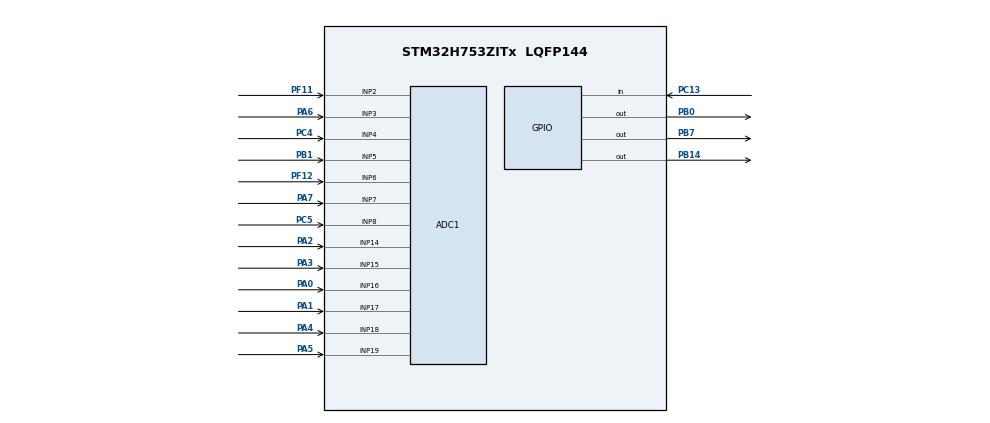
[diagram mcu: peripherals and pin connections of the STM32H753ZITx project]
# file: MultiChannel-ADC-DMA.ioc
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ADC1.Channel-0\#ChannelRegularConversion=ADC_CHANNEL_2
ADC1.Channel-1\#ChannelRegularConversion=ADC_CHANNEL_3
ADC1.Channel-10\#ChannelRegularConversion=ADC_CHANNEL_17
ADC1.Channel-11\#ChannelRegularConversion=ADC_CHANNEL_18
ADC1.Channel-12\#ChannelRegularConversion=ADC_CHANNEL_19
ADC1.Channel-2\#ChannelRegularConversion=ADC_CHANNEL_4
ADC1.Channel-3\#ChannelRegularConversion=ADC_CHANNEL_5
ADC1.Channel-4\#ChannelRegularConversion=ADC_CHANNEL_6
ADC1.Channel-5\#ChannelRegularConversion=ADC_CHANNEL_7
ADC1.Channel-6\#ChannelRegularConversion=ADC_CHANNEL_8
ADC1.Channel-7\#ChannelRegularConversion=ADC_CHANNEL_14
ADC1.Channel-8\#ChannelRegularConversion=ADC_CHANNEL_15
ADC1.Channel-9\#ChannelRegularConversion=ADC_CHANNEL_16
ADC1.ClockPrescaler=ADC_CLOCK_ASYNC_DIV8
ADC1.ContinuousConvMode=DISABLE
ADC1.ConversionDataManagement=ADC_CONVERSIONDATA_DMA_CIRCULAR
ADC1.EOCSelection=ADC_EOC_SEQ_CONV
ADC1.ExternalTrigConv=ADC_EXTERNALTRIG_T8_TRGO
ADC1.NbrOfConversion=13
ADC1.NbrOfConversionFlag=1
ADC1.OffsetNumber-0\#ChannelRegularConversion=ADC_OFFSET_NONE
ADC1.OffsetNumber-1\#ChannelRegularConversion=ADC_OFFSET_NONE
ADC1.OffsetNumber-10\#ChannelRegularConversion=ADC_OFFSET_NONE
ADC1.OffsetNumber-11\#ChannelRegularConversion=ADC_OFFSET_NONE
ADC1.OffsetNumber-12\#ChannelRegularConversion=ADC_OFFSET_NONE
ADC1.OffsetNumber-2\#ChannelRegularConversion=ADC_OFFSET_NONE
ADC1.OffsetNumber-3\#ChannelRegularConversion=ADC_OFFSET_NONE
ADC1.OffsetNumber-4\#ChannelRegularConversion=ADC_OFFSET_NONE
ADC1.OffsetNumber-5\#ChannelRegularConversion=ADC_OFFSET_NONE
ADC1.OffsetNumber-6\#ChannelRegularConversion=ADC_OFFSET_NONE
ADC1.OffsetNumber-7\#ChannelRegularConversion=ADC_OFFSET_NONE
ADC1.OffsetNumber-8\#ChannelRegularConversion=ADC_OFFSET_NONE
ADC1.OffsetNumber-9\#ChannelRegularConversion=ADC_OFFSET_NONE
ADC1.OffsetSignedSaturation-0\#ChannelRegularConversion=DISABLE
ADC1.OffsetSignedSaturation-1\#ChannelRegularConversion=DISABLE
ADC1.OffsetSignedSaturation-10\#ChannelRegularConversion=DISABLE
ADC1.OffsetSignedSaturation-11\#ChannelRegularConversion=DISABLE
ADC1.OffsetSignedSaturation-12\#ChannelRegularConversion=DISABLE
ADC1.OffsetSignedSaturation-2\#ChannelRegularConversion=DISABLE
ADC1.OffsetSignedSaturation-3\#ChannelRegularConversion=DISABLE
ADC1.OffsetSignedSaturation-4\#ChannelRegularConversion=DISABLE
ADC1.OffsetSignedSaturation-5\#ChannelRegularConversion=DISABLE
ADC1.OffsetSignedSaturation-6\#ChannelRegularConversion=DISABLE
ADC1.OffsetSignedSaturation-7\#ChannelRegularConversion=DISABLE
ADC1.OffsetSignedSaturation-8\#ChannelRegularConversion=DISABLE
ADC1.OffsetSignedSaturation-9\#ChannelRegularConversion=DISABLE
ADC1.Rank-0\#ChannelRegularConversion=1
ADC1.Rank-1\#ChannelRegularConversion=2
ADC1.Rank-10\#ChannelRegularConversion=11
ADC1.Rank-11\#ChannelRegularConversion=12
ADC1.Rank-12\#ChannelRegularConversion=13
ADC1.Rank-2\#ChannelRegularConversion=3
ADC1.Rank-3\#ChannelRegularConversion=4
ADC1.Rank-4\#ChannelRegularConversion=5
ADC1.Rank-5\#ChannelRegularConversion=6
ADC1.Rank-6\#ChannelRegularConversion=7
ADC1.Rank-7\#ChannelRegularConversion=8
ADC1.Rank-8\#ChannelRegularConversion=9
ADC1.Rank-9\#ChannelRegularConversion=10
ADC1.SamplingTime-0\#ChannelRegularConversion=ADC_SAMPLETIME_387CYCLES_5
ADC1.SamplingTime-1\#ChannelRegularConversion=ADC_SAMPLETIME_387CYCLES_5
ADC1.SamplingTime-10\#ChannelRegularConversion=ADC_SAMPLETIME_810CYCLES_5
ADC1.SamplingTime-11\#ChannelRegularConversion=ADC_SAMPLETIME_810CYCLES_5
ADC1.SamplingTime-12\#ChannelRegularConversion=ADC_SAMPLETIME_810CYCLES_5
ADC1.SamplingTime-2\#ChannelRegularConversion=ADC_SAMPLETIME_387CYCLES_5
ADC1.SamplingTime-3\#ChannelRegularConversion=ADC_SAMPLETIME_387CYCLES_5
ADC1.SamplingTime-4\#ChannelRegularConversion=ADC_SAMPLETIME_387CYCLES_5
ADC1.SamplingTime-5\#ChannelRegularConversion=ADC_SAMPLETIME_810CYCLES_5
ADC1.SamplingTime-6\#ChannelRegularConversion=ADC_SAMPLETIME_810CYCLES_5
ADC1.SamplingTime-7\#ChannelRegularConversion=ADC_SAMPLETIME_810CYCLES_5
ADC1.SamplingTime-8\#ChannelRegularConversion=ADC_SAMPLETIME_810CYCLES_5
ADC1.SamplingTime-9\#ChannelRegularConversion=ADC_SAMPLETIME_810CYCLES_5
ADC1.master=1
CORTEX_M7.AccessPermission_Spec=MPU_REGION_FULL_ACCESS
CORTEX_M7.BaseAddress_Spec=0x38000000
CORTEX_M7.CPU_DCache=Enabled
CORTEX_M7.CPU_ICache=Enabled
CORTEX_M7.IsShareable_Spec=MPU_ACCESS_NOT_SHAREABLE
CORTEX_M7.MPU_Control=MPU_PRIVILEGED_DEFAULT
CORTEX_M7.Size_Spec=MPU_REGION_SIZE_32KB
CORTEX_M7.SubRegionDisable_Spec=0x00
CORTEX_M7.default_mode_Activation=1
Dma.ADC1.0.Direction=DMA_PERIPH_TO_MEMORY
Dma.ADC1.0.EventEnable=DISABLE
Dma.ADC1.0.FIFOMode=DMA_FIFOMODE_DISABLE
Dma.ADC1.0.Instance=DMA1_Stream0
Dma.ADC1.0.MemDataAlignment=DMA_MDATAALIGN_HALFWORD
Dma.ADC1.0.MemInc=DMA_MINC_ENABLE
Dma.ADC1.0.Mode=DMA_CIRCULAR
Dma.ADC1.0.PeriphDataAlignment=DMA_PDATAALIGN_HALFWORD
Dma.ADC1.0.PeriphInc=DMA_PINC_DISABLE
Dma.ADC1.0.Polarity=HAL_DMAMUX_REQ_GEN_RISING
Dma.ADC1.0.Priority=DMA_PRIORITY_LOW
Dma.ADC1.0.RequestNumber=1
Dma.ADC1.0.SignalID=NONE
Dma.ADC1.0.SyncEnable=DISABLE
Dma.ADC1.0.SyncPolarity=HAL_DMAMUX_SYNC_NO_EVENT
Dma.ADC1.0.SyncRequestNumber=1
Dma.ADC1.0.SyncSignalID=NONE
Dma.Request0=ADC1
Mcu.Family=STM32H7
Mcu.Name=STM32H753ZITx
Mcu.Package=LQFP144
NUCLEO-H753ZI.BUTTON=1
NUCLEO-H753ZI.LD1=true
NUCLEO-H753ZI.LD2=true
NUCLEO-H753ZI.LD3=true
NUCLEO-H753ZI.VCP=true
NVIC.ADC_IRQn=true\:0\:0\:false\:false\:true\:true\:true\:true
NVIC.DMA1_Stream0_IRQn=true\:0\:0\:false\:false\:true\:false\:true\:true
NVIC.EXTI15_10_IRQn=true\:0\:0\:false\:false\:true\:false\:true\:true
NVIC.PriorityGroup=NVIC_PRIORITYGROUP_4
PA0.Mode=IN16-Single-Ended
PA0.Signal=ADC1_INP16
PA1.Mode=IN17-Single-Ended
PA1.Signal=ADC1_INP17
PA2.Signal=ADCx_INP14
PA3.Signal=ADCx_INP15
PA4.Signal=ADCx_INP18
PA5.Signal=ADCx_INP19
PA6.Signal=ADCx_INP3
PA7.Signal=ADCx_INP7
PB0.Signal=GPIO_Output
PB1.Signal=ADCx_INP5
PB14.Signal=GPIO_Output
PB7.Signal=GPIO_Output
PC13.Signal=GPIO_Input
PC14-OSC32_IN\ (OSC32_IN).Mode=LSE-External-Oscillator
PC14-OSC32_IN\ (OSC32_IN).Signal=RCC_OSC32_IN
PC15-OSC32_OUT\ (OSC32_OUT).Mode=LSE-External-Oscillator
PC15-OSC32_OUT\ (OSC32_OUT).Signal=RCC_OSC32_OUT
PC4.Signal=ADCx_INP4
PC5.Signal=ADCx_INP8
PD8.Signal=USART3_TX
PD9.Signal=USART3_RX
PF11.Mode=IN2-Single-Ended
PF11.Signal=ADC1_INP2
PF12.Mode=IN6-Single-Ended
PF12.Signal=ADC1_INP6
PH0-OSC_IN\ (PH0).Signal=RCC_OSC_IN
PH1-OSC_OUT\ (PH1).Signal=RCC_OSC_OUT
ProjectManager.HeapSize=0x200
ProjectManager.StackSize=0x400
ProjectManager.TargetToolchain=STM32CubeIDE
RCC.ADCFreq_Value=32000000
RCC.APB1Freq_Value=120000000
RCC.APB2Freq_Value=120000000
RCC.APB3Freq_Value=120000000
RCC.APB4Freq_Value=120000000
RCC.CortexFreq_Value=480000000
RCC.D1PPRE=RCC_APB3_DIV2
RCC.D2PPRE1=RCC_APB1_DIV2
RCC.D2PPRE2=RCC_APB2_DIV2
RCC.D3PPRE=RCC_APB4_DIV2
RCC.DIVM1=4
RCC.DIVM2=4
RCC.DIVN1=60
RCC.DIVN2=16
RCC.DIVN3=64
RCC.DIVP2=8
RCC.DIVQ1=4
RCC.HCLKFreq_Value=240000000
RCC.HPRE=RCC_HCLK_DIV2
RCC.HSE_VALUE=8000000
RCC.PLL2FRACN=0
RCC.PLL3FRACN=0
RCC.PLLFRACN=0
RCC.PWR_Regulator_Voltage_Scale=PWR_REGULATOR_VOLTAGE_SCALE0
RCC.SYSCLKFreq_VALUE=480000000
RCC.SYSCLKSource=RCC_SYSCLKSOURCE_PLLCLK
RCC.USBFreq_Value=240000000
SH.ADCx_INP14.0=ADC1_INP14,IN14-Single-Ended
SH.ADCx_INP15.0=ADC1_INP15,IN15-Single-Ended
SH.ADCx_INP18.0=ADC1_INP18,IN18-Single-Ended
SH.ADCx_INP19.0=ADC1_INP19,IN19-Single-Ended
SH.ADCx_INP3.0=ADC1_INP3,IN3-Single-Ended
SH.ADCx_INP4.0=ADC1_INP4,IN4-Single-Ended
SH.ADCx_INP5.0=ADC1_INP5,IN5-Single-Ended
SH.ADCx_INP7.0=ADC1_INP7,IN7-Single-Ended
SH.ADCx_INP8.0=ADC1_INP8,IN8-Single-Ended
TIM8.Period=200-1
TIM8.Prescaler=24000-1
TIM8.TIM_MasterOutputTrigger=TIM_TRGO_UPDATE
VP_MEMORYMAP_VS_MEMORYMAP.Mode=CurAppReg
VP_NUCLEO-H753ZI_VS_BSP_COMMON.Mode=COMMON
VP_TIM8_VS_ClockSourceINT.Mode=Internal
board=NUCLEO-H753ZI

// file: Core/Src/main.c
/* USER CODE BEGIN Header */
/**
  ******************************************************************************
  * @file           : main.c
  * @brief          : Main program body
  ******************************************************************************
  * @attention
  *
  * Copyright (c) 2025 STMicroelectronics.
  * All rights reserved.
  *
  * This software is licensed under terms that can be found in the LICENSE file
  * in the root directory of this software component.
  * If no LICENSE file comes with this software, it is provided AS-IS.
  *
  ******************************************************************************
  */
/* USER CODE END Header */
#include "main.h"

/* USER CODE BEGIN PD */
#define NUM_OF_CONVERSIONS 13
#define ADC_RAW_VOLTAGE 0.00005035477f
/* USER CODE END PD */

COM_InitTypeDef BspCOMInit;
ADC_HandleTypeDef hadc1;
DMA_HandleTypeDef hdma_adc1;

TIM_HandleTypeDef htim8;

/* USER CODE BEGIN PV */
volatile uint16_t adcData[NUM_OF_CONVERSIONS] __attribute__((section(".nocache")));
volatile float    sensorVoltage[NUM_OF_CONVERSIONS];
/* USER CODE END PV */

void SystemClock_Config(void);
static void MPU_Config(void);
static void MX_GPIO_Init(void);
static void MX_DMA_Init(void);
static void MX_ADC1_Init(void);
static void MX_TIM8_Init(void);

/* USER CODE BEGIN 0 */
void HAL_ADC_ConvCpltCallback(ADC_HandleTypeDef *had) {
	for (uint8_t index = 0; index<NUM_OF_CONVERSIONS; index++) {
		sensorVoltage[index] = ADC_RAW_VOLTAGE * (float) adcData[index];
	}
}
/* USER CODE END 0 */

int main(void)
{

  /* MPU Configuration--------------------------------------------------------*/
  MPU_Config();

  /* Enable the CPU Cache */

  /* Enable I-Cache---------------------------------------------------------*/
  SCB_EnableICache();

  /* Enable D-Cache---------------------------------------------------------*/
  SCB_EnableDCache();

  /* MCU Configuration--------------------------------------------------------*/

  /* Reset of all peripherals, Initializes the Flash interface and the Systick. */
  HAL_Init();

  /* Configure the system clock */
  SystemClock_Config();

  /* Initialize all configured peripherals */
  MX_GPIO_Init();
  MX_DMA_Init();
  MX_ADC1_Init();
  MX_TIM8_Init();
  /* USER CODE BEGIN 2 */
  HAL_ADCEx_Calibration_Start(&hadc1, ADC_CALIB_OFFSET, ADC_SINGLE_ENDED);//Calibrating ADC before enbaling conversions
  HAL_ADC_Start_DMA(&hadc1, (uint32_t *)adcData, NUM_OF_CONVERSIONS);//Starting DMA based ADC
  HAL_TIM_Base_Start(&htim8); //50Hz sampling frequency
  /* USER CODE END 2 */

  /* Initialize leds */
  BSP_LED_Init(LED_GREEN);
  BSP_LED_Init(LED_BLUE);
  BSP_LED_Init(LED_RED);

  /* Initialize USER push-button, will be used to trigger an interrupt each time it's pressed.*/
  BSP_PB_Init(BUTTON_USER, BUTTON_MODE_EXTI);

  /* Initialize COM1 port (115200, 8 bits (7-bit data + 1 stop bit), no parity */
  BspCOMInit.BaudRate   = 115200;
  BspCOMInit.WordLength = COM_WORDLENGTH_8B;
  BspCOMInit.StopBits   = COM_STOPBITS_1;
  BspCOMInit.Parity     = COM_PARITY_NONE;
  BspCOMInit.HwFlowCtl  = COM_HWCONTROL_NONE;
  if (BSP_COM_Init(COM1, &BspCOMInit) != BSP_ERROR_NONE)
  {
    Error_Handler();
  }

  /* Infinite loop */
  while (1)
  {

  }
}

void SystemClock_Config(void)
{
  RCC_OscInitTypeDef RCC_OscInitStruct = {0};
  RCC_ClkInitTypeDef RCC_ClkInitStruct = {0};

  /** Supply configuration update enable
  */
  HAL_PWREx_ConfigSupply(PWR_LDO_SUPPLY);

  /** Configure the main internal regulator output voltage
  */
  __HAL_PWR_VOLTAGESCALING_CONFIG(PWR_REGULATOR_VOLTAGE_SCALE0);

  while(!__HAL_PWR_GET_FLAG(PWR_FLAG_VOSRDY)) {}

  /** Initializes the RCC Oscillators according to the specified parameters
  * in the RCC_OscInitTypeDef structure.
  */
  RCC_OscInitStruct.OscillatorType = RCC_OSCILLATORTYPE_HSI;
  RCC_OscInitStruct.HSIState = RCC_HSI_DIV1;
  RCC_OscInitStruct.HSICalibrationValue = RCC_HSICALIBRATION_DEFAULT;
  RCC_OscInitStruct.PLL.PLLState = RCC_PLL_ON;
  RCC_OscInitStruct.PLL.PLLSource = RCC_PLLSOURCE_HSI;
  RCC_OscInitStruct.PLL.PLLM = 4;
  RCC_OscInitStruct.PLL.PLLN = 60;
  RCC_OscInitStruct.PLL.PLLP = 2;
  RCC_OscInitStruct.PLL.PLLQ = 4;
  RCC_OscInitStruct.PLL.PLLR = 2;
  RCC_OscInitStruct.PLL.PLLRGE = RCC_PLL1VCIRANGE_3;
  RCC_OscInitStruct.PLL.PLLVCOSEL = RCC_PLL1VCOWIDE;
  RCC_OscInitStruct.PLL.PLLFRACN = 0;
  if (HAL_RCC_OscConfig(&RCC_OscInitStruct) != HAL_OK)
  {
    Error_Handler();
  }

  /** Initializes the CPU, AHB and APB buses clocks
  */
  RCC_ClkInitStruct.ClockType = RCC_CLOCKTYPE_HCLK|RCC_CLOCKTYPE_SYSCLK
                              |RCC_CLOCKTYPE_PCLK1|RCC_CLOCKTYPE_PCLK2
                              |RCC_CLOCKTYPE_D3PCLK1|RCC_CLOCKTYPE_D1PCLK1;
  RCC_ClkInitStruct.SYSCLKSource = RCC_SYSCLKSOURCE_PLLCLK;
  RCC_ClkInitStruct.SYSCLKDivider = RCC_SYSCLK_DIV1;
  RCC_ClkInitStruct.AHBCLKDivider = RCC_HCLK_DIV2;
  RCC_ClkInitStruct.APB3CLKDivider = RCC_APB3_DIV2;
  RCC_ClkInitStruct.APB1CLKDivider = RCC_APB1_DIV2;
  RCC_ClkInitStruct.APB2CLKDivider = RCC_APB2_DIV2;
  RCC_ClkInitStruct.APB4CLKDivider = RCC_APB4_DIV2;

  if (HAL_RCC_ClockConfig(&RCC_ClkInitStruct, FLASH_LATENCY_4) != HAL_OK)
  {
    Error_Handler();
  }
}

static void MX_ADC1_Init(void)
{

  ADC_MultiModeTypeDef multimode = {0};
  ADC_ChannelConfTypeDef sConfig = {0};

  /** Common config
  */
  hadc1.Instance = ADC1;
  hadc1.Init.ClockPrescaler = ADC_CLOCK_ASYNC_DIV8;
  hadc1.Init.Resolution = ADC_RESOLUTION_16B;
  hadc1.Init.ScanConvMode = ADC_SCAN_ENABLE;
  hadc1.Init.EOCSelection = ADC_EOC_SEQ_CONV;
  hadc1.Init.LowPowerAutoWait = DISABLE;
  hadc1.Init.ContinuousConvMode = DISABLE;
  hadc1.Init.NbrOfConversion = 13;
  hadc1.Init.DiscontinuousConvMode = DISABLE;
  hadc1.Init.ExternalTrigConv = ADC_EXTERNALTRIG_T8_TRGO;
  hadc1.Init.ExternalTrigConvEdge = ADC_EXTERNALTRIGCONVEDGE_RISING;
  hadc1.Init.ConversionDataManagement = ADC_CONVERSIONDATA_DMA_CIRCULAR;
  hadc1.Init.Overrun = ADC_OVR_DATA_PRESERVED;
  hadc1.Init.LeftBitShift = ADC_LEFTBITSHIFT_NONE;
  hadc1.Init.OversamplingMode = DISABLE;
  hadc1.Init.Oversampling.Ratio = 1;
  if (HAL_ADC_Init(&hadc1) != HAL_OK)
  {
    Error_Handler();
  }

  /** Configure the ADC multi-mode
  */
  multimode.Mode = ADC_MODE_INDEPENDENT;
  if (HAL_ADCEx_MultiModeConfigChannel(&hadc1, &multimode) != HAL_OK)
  {
    Error_Handler();
  }

  /** Configure Regular Channel
  */
  sConfig.Channel = ADC_CHANNEL_2;
  sConfig.Rank = ADC_REGULAR_RANK_1;
  sConfig.SamplingTime = ADC_SAMPLETIME_387CYCLES_5;
  sConfig.SingleDiff = ADC_SINGLE_ENDED;
  sConfig.OffsetNumber = ADC_OFFSET_NONE;
  sConfig.Offset = 0;
  sConfig.OffsetSignedSaturation = DISABLE;
  if (HAL_ADC_ConfigChannel(&hadc1, &sConfig) != HAL_OK)
  {
    Error_Handler();
  }

  /** Configure Regular Channel
  */
  sConfig.Channel = ADC_CHANNEL_3;
  sConfig.Rank = ADC_REGULAR_RANK_2;
  if (HAL_ADC_ConfigChannel(&hadc1, &sConfig) != HAL_OK)
  {
    Error_Handler();
  }

  /** Configure Regular Channel
  */
  sConfig.Channel = ADC_CHANNEL_4;
  sConfig.Rank = ADC_REGULAR_RANK_3;
  if (HAL_ADC_ConfigChannel(&hadc1, &sConfig) != HAL_OK)
  {
    Error_Handler();
  }

  /** Configure Regular Channel
  */
  sConfig.Channel = ADC_CHANNEL_5;
  sConfig.Rank = ADC_REGULAR_RANK_4;
  if (HAL_ADC_ConfigChannel(&hadc1, &sConfig) != HAL_OK)
  {
    Error_Handler();
  }

  /** Configure Regular Channel
  */
  sConfig.Channel = ADC_CHANNEL_6;
  sConfig.Rank = ADC_REGULAR_RANK_5;
  if (HAL_ADC_ConfigChannel(&hadc1, &sConfig) != HAL_OK)
  {
    Error_Handler();
  }

  /** Configure Regular Channel
  */
  sConfig.Channel = ADC_CHANNEL_7;
  sConfig.Rank = ADC_REGULAR_RANK_6;
  sConfig.SamplingTime = ADC_SAMPLETIME_810CYCLES_5;
  if (HAL_ADC_ConfigChannel(&hadc1, &sConfig) != HAL_OK)
  {
    Error_Handler();
  }

  /** Configure Regular Channel
  */
  sConfig.Channel = ADC_CHANNEL_8;
  sConfig.Rank = ADC_REGULAR_RANK_7;
  if (HAL_ADC_ConfigChannel(&hadc1, &sConfig) != HAL_OK)
  {
    Error_Handler();
  }

  /** Configure Regular Channel
  */
  sConfig.Channel = ADC_CHANNEL_14;
  sConfig.Rank = ADC_REGULAR_RANK_8;
  if (HAL_ADC_ConfigChannel(&hadc1, &sConfig) != HAL_OK)
  {
    Error_Handler();
  }

  /** Configure Regular Channel
  */
  sConfig.Channel = ADC_CHANNEL_15;
  sConfig.Rank = ADC_REGULAR_RANK_9;
  if (HAL_ADC_ConfigChannel(&hadc1, &sConfig) != HAL_OK)
  {
    Error_Handler();
  }

  /** Configure Regular Channel
  */
  sConfig.Channel = ADC_CHANNEL_16;
  sConfig.Rank = ADC_REGULAR_RANK_10;
  if (HAL_ADC_ConfigChannel(&hadc1, &sConfig) != HAL_OK)
  {
    Error_Handler();
  }

  /** Configure Regular Channel
  */
  sConfig.Channel = ADC_CHANNEL_17;
  sConfig.Rank = ADC_REGULAR_RANK_11;
  if (HAL_ADC_ConfigChannel(&hadc1, &sConfig) != HAL_OK)
  {
    Error_Handler();
  }

  /** Configure Regular Channel
  */
  sConfig.Channel = ADC_CHANNEL_18;
  sConfig.Rank = ADC_REGULAR_RANK_12;
  if (HAL_ADC_ConfigChannel(&hadc1, &sConfig) != HAL_OK)
  {
    Error_Handler();
  }

  /** Configure Regular Channel
  */
  sConfig.Channel = ADC_CHANNEL_19;
  sConfig.Rank = ADC_REGULAR_RANK_13;
  if (HAL_ADC_ConfigChannel(&hadc1, &sConfig) != HAL_OK)
  {
    Error_Handler();
  }

}

static void MX_TIM8_Init(void)
{

  TIM_ClockConfigTypeDef sClockSourceConfig = {0};
  TIM_MasterConfigTypeDef sMasterConfig = {0};

  htim8.Instance = TIM8;
  htim8.Init.Prescaler = 24000-1;
  htim8.Init.CounterMode = TIM_COUNTERMODE_UP;
  htim8.Init.Period = 200-1;
  htim8.Init.ClockDivision = TIM_CLOCKDIVISION_DIV1;
  htim8.Init.RepetitionCounter = 0;
  htim8.Init.AutoReloadPreload = TIM_AUTORELOAD_PRELOAD_DISABLE;
  if (HAL_TIM_Base_Init(&htim8) != HAL_OK)
  {
    Error_Handler();
  }
  sClockSourceConfig.ClockSource = TIM_CLOCKSOURCE_INTERNAL;
  if (HAL_TIM_ConfigClockSource(&htim8, &sClockSourceConfig) != HAL_OK)
  {
    Error_Handler();
  }
  sMasterConfig.MasterOutputTrigger = TIM_TRGO_UPDATE;
  sMasterConfig.MasterOutputTrigger2 = TIM_TRGO2_RESET;
  sMasterConfig.MasterSlaveMode = TIM_MASTERSLAVEMODE_DISABLE;
  if (HAL_TIMEx_MasterConfigSynchronization(&htim8, &sMasterConfig) != HAL_OK)
  {
    Error_Handler();
  }

}

static void MX_DMA_Init(void)
{

  /* DMA controller clock enable */
  __HAL_RCC_DMA1_CLK_ENABLE();

  /* DMA interrupt init */
  /* DMA1_Stream0_IRQn interrupt configuration */
  HAL_NVIC_SetPriority(DMA1_Stream0_IRQn, 0, 0);
  HAL_NVIC_EnableIRQ(DMA1_Stream0_IRQn);

}

static void MX_GPIO_Init(void)
{

  /* GPIO Ports Clock Enable */
  __HAL_RCC_GPIOC_CLK_ENABLE();
  __HAL_RCC_GPIOH_CLK_ENABLE();
  __HAL_RCC_GPIOA_CLK_ENABLE();
  __HAL_RCC_GPIOB_CLK_ENABLE();
  __HAL_RCC_GPIOF_CLK_ENABLE();

}

 /* MPU Configuration */

void MPU_Config(void)
{
  MPU_Region_InitTypeDef MPU_InitStruct = {0};

  /* Disables the MPU */
  HAL_MPU_Disable();

  /** Initializes and configures the Region and the memory to be protected
  */
  MPU_InitStruct.Enable = MPU_REGION_ENABLE;
  MPU_InitStruct.Number = MPU_REGION_NUMBER0;
  MPU_InitStruct.BaseAddress = 0x38000000;
  MPU_InitStruct.Size = MPU_REGION_SIZE_32KB;
  MPU_InitStruct.SubRegionDisable = 0x00;
  MPU_InitStruct.TypeExtField = MPU_TEX_LEVEL0;
  MPU_InitStruct.AccessPermission = MPU_REGION_FULL_ACCESS;
  MPU_InitStruct.DisableExec = MPU_INSTRUCTION_ACCESS_DISABLE;
  MPU_InitStruct.IsShareable = MPU_ACCESS_NOT_SHAREABLE;
  MPU_InitStruct.IsCacheable = MPU_ACCESS_NOT_CACHEABLE;
  MPU_InitStruct.IsBufferable = MPU_ACCESS_NOT_BUFFERABLE;

  HAL_MPU_ConfigRegion(&MPU_InitStruct);
  /* Enables the MPU */
  HAL_MPU_Enable(MPU_PRIVILEGED_DEFAULT);

}

void Error_Handler(void)
{
  __disable_irq();
  while (1)
  {
  }
}
